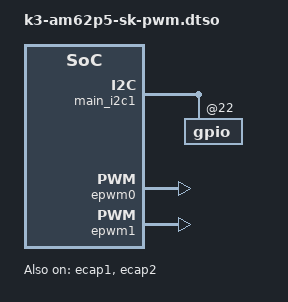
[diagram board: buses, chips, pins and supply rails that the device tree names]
// SPDX-License-Identifier: GPL-2.0
/**
 * DT Overlay for enabling PWM output on user expansion connector for AM62p5-SK
 *
 * Copyright (C) 2023 Texas Instruments Incorporated - https://www.ti.com/
 */

/dts-v1/;
/plugin/;

#include <dt-bindings/gpio/gpio.h>
#include "k3-pinctrl.h"

&main_pmx0 {
	main_epwm0_pins_default: main_epwm0-default-pins {
		pinctrl-single,pins = <
			AM62PX_IOPAD(0x01b4, PIN_OUTPUT, 2) /* (D20) SPI0_CS0.EHRPWM0_A */
			AM62PX_IOPAD(0x01b8, PIN_OUTPUT, 2) /* (E20) SPI0_CS1.EHRPWM0_B */
		>;
	};
	main_epwm1_pins_default: main_epwm1-default-pins {
		pinctrl-single,pins = <
			AM62PX_IOPAD(0x01bc, PIN_OUTPUT, 2) /* (B21) SPI0_CLK.EHRPWM1_A */
			AM62PX_IOPAD(0x01c0, PIN_OUTPUT, 2) /* (B20) SPI0_D0.EHRPWM1_B */
		>;
	};
	main_ecap1_pins_default: main_ecap1-default-pins {
		pinctrl-single,pins = <
			AM62PX_IOPAD(0x019c, PIN_OUTPUT, 2) /* (E24) MCASP0_AXR1.ECAP1_IN_APWM_OUT */
		>;
	};
	main_ecap2_pins_default: main-ecap2-default-pins {
		pinctrl-single,pins = <
			AM62PX_IOPAD(0x01a4, PIN_OUTPUT, 2) /* (F24) MCASP0_ACLKX.ECAP2_IN_APWM_OUT */
		>;
	};
};

&main_i2c1 {
	gpio@22 {
		fet_sel {
			gpio-hog;
			gpios = <21 GPIO_ACTIVE_HIGH>;
			output-low;
			line-name = "UART1_FET_SEL";
		};
	};
};

&epwm0 {
	/* Pin 24/26 of J4 */
	pinctrl-names = "default";
	pinctrl-0 = <&main_epwm0_pins_default>;
	status = "okay";
};

&epwm1 {
	/* Pin 23/19 of J4 */
	pinctrl-names = "default";
	pinctrl-0 = <&main_epwm1_pins_default>;
	status = "okay";
};

&ecap1 {
	/* ECAP1 in APWM mode */
	/* Pin 36 of J4 */
	pinctrl-names = "default";
	pinctrl-0 = <&main_ecap1_pins_default>;
	status = "okay";
};

&ecap2 {
	/* ECAP2 in APWM mode */
	/* Pin 11 of J4 */
	pinctrl-names = "default";
	pinctrl-0 = <&main_ecap2_pins_default>;
	status = "okay";
};
